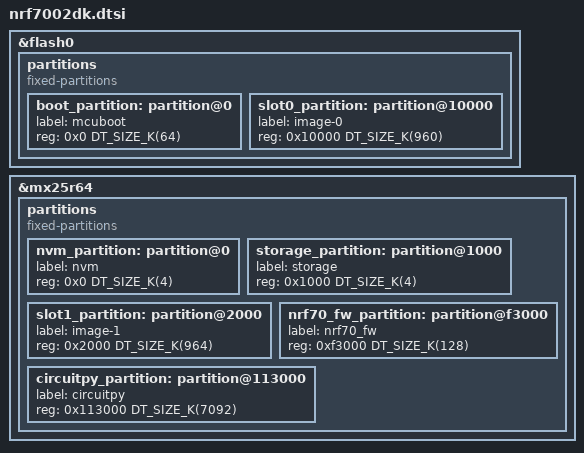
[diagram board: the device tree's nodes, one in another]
&flash0 {
	partitions {
		compatible = "fixed-partitions";
		#address-cells = <1>;
		#size-cells = <1>;

		boot_partition: partition@0 {
			label = "mcuboot";
			reg = <0x0 DT_SIZE_K(64)>;
		};

		slot0_partition: partition@10000 {
			label = "image-0";
			reg = <0x10000 DT_SIZE_K(960)>;
		};
	};
};

&mx25r64 {
	partitions {
		compatible = "fixed-partitions";
		#address-cells = <1>;
		#size-cells = <1>;

		nvm_partition: partition@0 {
			label = "nvm";
			reg = <0x0 DT_SIZE_K(4)>;
		};

		storage_partition: partition@1000 {
			label = "storage";
			reg = <0x1000 DT_SIZE_K(4)>;
		};

		slot1_partition: partition@2000 {
			label = "image-1";
			reg = <0x2000 DT_SIZE_K(964)>;
		};

		nrf70_fw_partition: partition@f3000 {
			label = "nrf70_fw";
			reg = <0xf3000 DT_SIZE_K(128)>;
		};

		circuitpy_partition: partition@113000 {
			label = "circuitpy";
			reg = <0x113000 DT_SIZE_K(7092)>;
		};
	};
};
